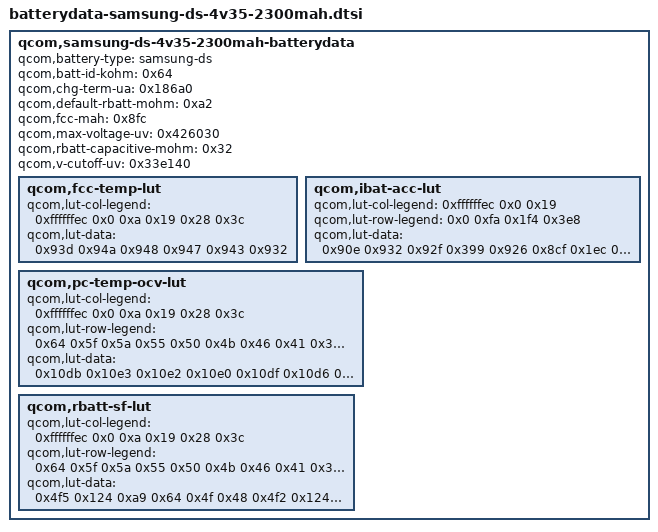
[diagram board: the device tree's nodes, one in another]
/* Copyright (c) 2018, The Linux Foundation. All rights reserved.
*
* This program is free software; you can redistribute it and/or modify
* it under the terms of the GNU General Public License version 2 and
* only version 2 as published by the Free Software Foundation.
*
* This program is distributed in the hope that it will be useful,
* but WITHOUT ANY WARRANTY; without even the implied warranty of
* MERCHANTABILITY or FITNESS FOR A PARTICULAR PURPOSE.  See the
* GNU General Public License for more details.
*/

qcom,samsung-ds-4v35-2300mah-batterydata {
	qcom,battery-type = "samsung-ds";
	qcom,batt-id-kohm = <0x64>;
	qcom,chg-term-ua = <0x186a0>;
	qcom,default-rbatt-mohm = <0xa2>;
	qcom,fcc-mah = <0x8fc>;
	qcom,max-voltage-uv = <0x426030>;
	qcom,rbatt-capacitive-mohm = <0x32>;
	qcom,v-cutoff-uv = <0x33e140>;

	qcom,fcc-temp-lut {
		qcom,lut-col-legend = <0xffffffec 0x0 0xa 0x19 0x28 0x3c>;
		qcom,lut-data = <0x93d 0x94a 0x948 0x947 0x943 0x932>;
	};

	qcom,ibat-acc-lut {
		qcom,lut-col-legend = <0xffffffec 0x0 0x19>;
		qcom,lut-row-legend = <0x0 0xfa 0x1f4 0x3e8>;
		qcom,lut-data = <0x90e 0x932 0x92f 0x399 0x926 0x8cf 0x1ec 0x8b8 0x8c0 0x27 0x71a 0x8b4>;
	};

	qcom,pc-temp-ocv-lut {
		qcom,lut-col-legend = <0xffffffec 0x0 0xa 0x19 0x28 0x3c>;
		qcom,lut-row-legend = <0x64 0x5f 0x5a 0x55 0x50 0x4b 0x46 0x41 0x3c 0x37 0x32 0x2d 0x28 0x23 0x1e 0x19 0x14 0x10 0xd 0xb 0xa 0x9 0x8 0x7 0x6 0x5 0x4 0x3 0x2 0x1 0x0>;
		qcom,lut-data = <0x10db 0x10e3 0x10e2 0x10e0 0x10df 0x10d6 0x107a 0x109a 0x109f 0x10a2 0x10a1 0x109c 0x1036 0x1062 0x1068 0x106b 0x106a 0x1065 0x1004 0x102f 0x1034 0x1036 0x1035 0x1031 0xfce 0xffe 0x1003 0x1004 0x1002 0xffe 0xf71 0xfd0 0xfd7 0xfd5 0xfd1 0xfce 0xf4a 0xf80 0xf93 0xf9c 0xfa1 0xfa2 0xf24 0xf55 0xf68 0xf7a 0xf7d 0xf7b 0xf01 0xf36 0xf41 0xf50 0xf54 0xf53 0xeeb 0xf15 0xf1c 0xf22 0xf24 0xf23 0xed9 0xefa 0xeff 0xf02 0xf03 0xf03 0xeca 0xee3 0xee8 0xeeb 0xeec 0xeec 0xebc 0xed0 0xed6 0xed9 0xeda 0xed9 0xeae 0xec4 0xec7 0xec9 0xec9 0xec9 0xe9f 0xeb8 0xebc 0xebc 0xeb9 0xeb5 0xe90 0xeaa 0xeb1 0xeae 0xea7 0xe9b 0xe81 0xe96 0xe9f 0xe9c 0xe94 0xe86 0xe71 0xe84 0xe88 0xe85 0xe7d 0xe70 0xe63 0xe7a 0xe75 0xe6e 0xe66 0xe59 0xe56 0xe73 0xe6f 0xe69 0xe61 0xe56 0xe4e 0xe70 0xe6d 0xe68 0xe60 0xe55 0xe45 0xe6d 0xe6b 0xe66 0xe60 0xe54 0xe3b 0xe6b 0xe6a 0xe65 0xe5e 0xe53 0xe2d 0xe65 0xe67 0xe63 0xe5c 0xe50 0xe1c 0xe5d 0xe61 0xe5e 0xe56 0xe47 0xe06 0xe4c 0xe50 0xe4d 0xe40 0xe2d 0xde6 0xe29 0xe2a 0xe1f 0xe14 0xe00 0xdba 0xdf3 0xdf0 0xde2 0xdd9 0xdc4 0xd75 0xda5 0xda0 0xd90 0xd8a 0xd71 0xcfb 0xd27 0xd22 0xd0d 0xd17 0xcef 0xbb8 0xbb8 0xbb8 0xbb8 0xbf4 0xbb8>;
	};

	qcom,rbatt-sf-lut {
		qcom,lut-col-legend = <0xffffffec 0x0 0xa 0x19 0x28 0x3c>;
		qcom,lut-row-legend = <0x64 0x5f 0x5a 0x55 0x50 0x4b 0x46 0x41 0x3c 0x37 0x32 0x2d 0x28 0x23 0x1e 0x19 0x14 0x10 0xd 0xb 0xa 0x9 0x8 0x7 0x6 0x5 0x4 0x3 0x2 0x1 0x0>;
		qcom,lut-data = <0x4f5 0x124 0xa9 0x64 0x4f 0x48 0x4f2 0x124 0xaa 0x64 0x4f 0x48 0x490 0x120 0xac 0x65 0x50 0x48 0x453 0x121 0xae 0x67 0x52 0x49 0x422 0x122 0xb3 0x6b 0x55 0x4b 0x3bd 0x12f 0xbe 0x70 0x57 0x4c 0x3b2 0x104 0xb6 0x72 0x5a 0x4e 0x3a8 0xfc 0xb1 0x7c 0x60 0x52 0x3a2 0xfa 0xa4 0x76 0x62 0x55 0x3b1 0xf5 0x9b 0x64 0x55 0x4c 0x3c8 0xf6 0x99 0x60 0x50 0x49 0x3e7 0xf9 0x9b 0x61 0x51 0x4a 0x40d 0xff 0x9e 0x64 0x54 0x4c 0x43a 0x10d 0xa1 0x67 0x57 0x4f 0x46f 0x11e 0xa9 0x69 0x56 0x4e 0x4ad 0x130 0xb3 0x68 0x53 0x4a 0x4f5 0x13f 0xba 0x67 0x53 0x4a 0x52a 0x14c 0xbe 0x68 0x53 0x4b 0x515 0x155 0xba 0x64 0x51 0x48 0x519 0x164 0xbf 0x65 0x51 0x49 0x538 0x16f 0xc6 0x67 0x53 0x4b 0x556 0x17e 0xcc 0x6a 0x55 0x4c 0x578 0x18c 0xd7 0x6e 0x57 0x4d 0x59a 0x1a0 0xe1 0x71 0x59 0x50 0x5bc 0x1b4 0xed 0x76 0x5b 0x50 0x5ee 0x1c4 0xf5 0x74 0x57 0x4c 0x689 0x1ce 0xf7 0x71 0x56 0x4c 0x7aa 0x1e4 0x102 0x75 0x58 0x4d 0x970 0x20d 0x119 0x7c 0x5c 0x52 0xe8c 0x256 0x14b 0xa0 0x66 0x5f 0x1883c 0x19010 0x185ab 0x1705b 0x119 0xfea8>;
	};
};
